AUTOSAR XML (schema 314)
package /ComponentType
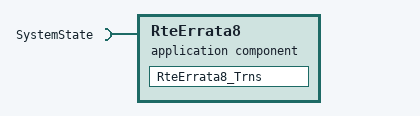
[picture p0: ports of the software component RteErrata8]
  application software component type RteErrata8  # This SWC contains definitions required to workaround Rte Generation errata following: 1) ESCAN00059438AN00059438 (corrected in Rte 2.22.00)
    require port SystemState: required-interface=SystemState
  internal behavior RteErrata8_InternalBehavior: component=RteErrata8, port-api-option{enable-take-address=false, indirect-api=false, port=SystemState}
    4 x mode switch event, all with start-on-event=RteErrata8_Trns, activation=ENTRY:
      MST_RteErrata8_Trns_0: mode=SystemState.Mode.OPERATE
      MST_RteErrata8_Trns_1: mode=SystemState.Mode.DISABLE
      MST_RteErrata8_Trns_2: mode=SystemState.Mode.WARMINIT
      MST_RteErrata8_Trns_3: mode=SystemState.Mode.OFF
    runnable RteErrata8_Trns
  swc implementation RteErrata8_Implementation: behavior=RteErrata8_InternalBehavior
    code-descriptors:
      code Code: type=SRC
